# AE350_4GB register map
Vendor: Andes Technology; Series: AE350; File version: 1.3.0
Registers are 32-bit, read-write, reset 0x0 unless marked. A register's access mark holds for its fields unless they carry their own. Offsets are from the block's base; [hi:lo] are bit positions; {n}, {i} and the like mark numbered series; 'fields as' and 'values as' point back to an identical list.

## I_2C — I^2C Controller Registers
Base 0xF0A00000
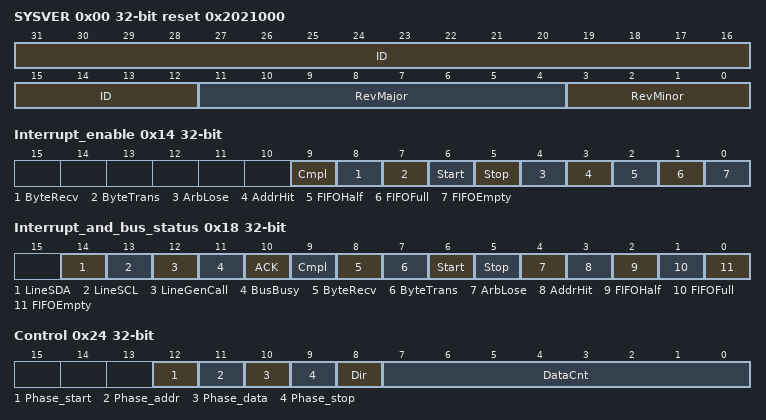
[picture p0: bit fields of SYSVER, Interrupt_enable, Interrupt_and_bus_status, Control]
0x00 SYSVER ro reset 0x2021000 — ID and Revision Register
  [31:12] ID — ID number for ATCIIC100
  [11:4] RevMajor — Major revision number
  [3:0] RevMinor — Minor revision number
0x10 Configuration ro reset not defined
  [1:0] FIFOSize
0x14 Interrupt_enable
  [9] Cmpl — Set to enable the Completion Interrupt
  [8] ByteRecv — Set to enable the Byte Receive Interrupt
  [7] ByteTrans — Set to enable the Byte Transmit Interrupt
  [6] Start — Set to enable the START Condition Interrupt
  [5] Stop — Set to enable the STOP Condition Interrupt
  [4] ArbLose — Set to enable the Arbitration Lose Interrupt
  [3] AddrHit — Set to enable the Address Hit Interrupt
  [2] FIFOHalf — Set to enable the FIFO Half Interrupt
  [1] FIFOFull — Set to enable the FIFO Full Interrupt
  [0] FIFOEmpty — Set to enable the FIFO Empty Interrupt
0x18 Interrupt_and_bus_status
  [14] LineSDA — Indicates the current status of the SDA line on the bus
  [13] LineSCL — Indicates the current status of the SCL line on the bus
  [12] LineGenCall — Indicates that the address of the current transaction is a general call address
  [11] BusBusy — Indicates that the bus is busy
  [10] ACK — Indicates the type of the last received/transmitted acknowledgement bit
  [9] Cmpl — Transaction Completion
  [8] ByteRecv — Indicates that a byte of data has been received
  [7] ByteTrans — Indicates that a byte of data has been transmitted
  [6] Start — Indicates that a START Condition or a repeated START condition has been transmitted/received
  [5] Stop — Indicates that a STOP Condition has been transmitted/received
  [4] ArbLose — Indicates that the controller has lost the bus arbitration
  [3] AddrHit — Master: indicates that a slave has responded to the transaction Slave: indicates that a transaction is targeting the controller (including the General Call)
  [2] FIFOHalf ro — Transmitter: Indicates that the FIFO is half-full. Receiver: Indicates that the FIFO is half-empty.
  [1] FIFOFull ro — Indicates that the FIFO is full
  [0] FIFOEmpty ro — Indicates that the FIFO is empty
0x1C Address
  [9:0] Addr — The slave address
0x20 Data
  [7:0] Data — Write this register to put one byte of data to the FIFO
0x24 Control
  [12] Phase_start — Enable this bit to send a START condition at the beginning of transaction
  [11] Phase_addr — Enable this bit to send the address after START condition
  [10] Phase_data — Enable this bit to send the data after Address phase
  [9] Phase_stop — Enable this bit to send a STOP condition at the end of a transaction
  [8] Dir — Transaction direction
  [7:0] DataCnt — Transaction direction
0x28 Command
  [2:0] CMD — Write this register
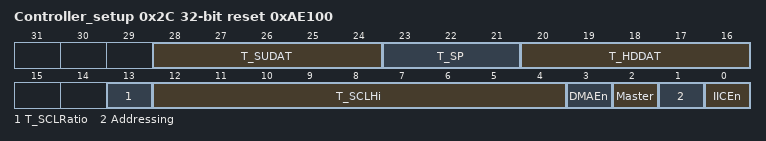
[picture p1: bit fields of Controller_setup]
0x2C Controller_setup reset 0xAE100
  [28:24] T_SUDAT — T_SUDAT defines the data setup time before releasing the SCL
  [23:21] T_SP — T_SP defines the pulse width of spikes that must be suppressed by the input filter
  [20:16] T_HDDAT — T_SUDAT defines the data hold time after SCL goes LOW
  [13] T_SCLRatio — The LOW period of the generated SCL clock is defined by the combination of T_SCLRatio and T_SCLHi values
  [12:4] T_SCLHi — The HIGH period of generated SCL clock is defined by T_SCLHi
  [3] DMAEn — Enable the direct memory access mode data transfer
  [2] Master — Configure this device as a master or a slave
  [1] Addressing — IIC addressing mode
  [0] IICEn — Enable the ATCIIC100 IIC controller
0x30 Timing_Parameter_Multiplier
  [4:0] TPM_TPM

## DMAC — DMA Controller Registers
Base 0xF0C00000
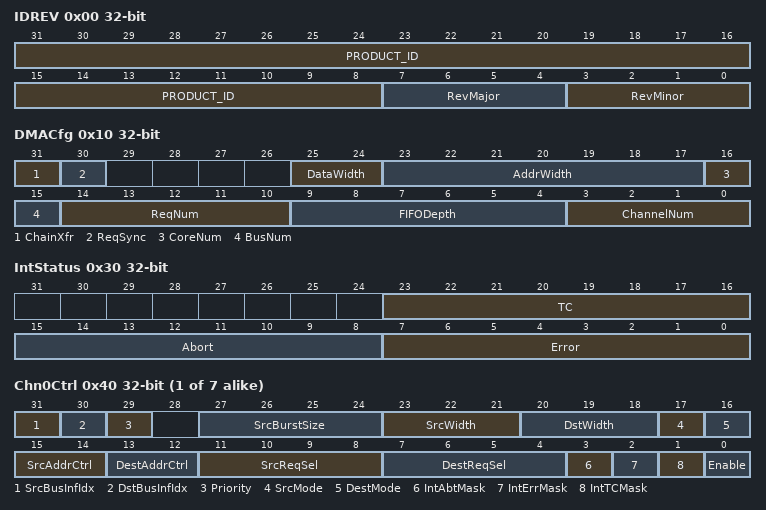
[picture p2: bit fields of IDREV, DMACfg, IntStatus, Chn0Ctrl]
0x00 IDREV ro — ID and Revision Register
  [31:8] PRODUCT_ID — ID number for DMAC(ATCDMAC300 )
  [7:4] RevMajor — Major revision number
  [3:0] RevMinor — Minor revision number
0x10 DMACfg ro — DMAC Configuration Register
  [31] ChainXfr — Chain transfer
  [30] ReqSync — DMA request synchronization
  [25:24] DataWidth — AXI bus data width
  [23:17] AddrWidth — AXI bus address width
  [16] CoreNum — DMA core number
  [15] BusNum — AXI bus interface number
  [14:10] ReqNum — Request/acknowledge pair number
  [9:4] FIFODepth
  [3:0] ChannelNum — Channel number
0x20 DMACtrl — DMAC Control Register
  [0] Reset wo — Software reset control.
0x24 ChAbort wo — Channel Abort Register
  [?] FIELD_1 rw
0x30 IntStatus — Interrupt Status Register
  [23:16] TC — The terminal count status of DMA channels, one bit per channel.
  [15:8] Abort — The abort status of channel, one bit per channel.
  [7:0] Error — The error status, one bit per channel.
0x34 ChEN ro — Channel Enable Register
  [31:0] ChEN — Alias of the Enable field of all ChnCtrl registers
{0x40+0x20*i} Chn{i}Ctrl (i=0..6) — Channel {i} Control Register
  [31] SrcBusInfIdx ro — Bus interface index that source data is read from
  [30] DstBusInfIdx ro — Bus interface index that source data is read from
  [29] Priority ro — Channel priority level
  [27:24] SrcBurstSize ro — Source burst size
  [23:21] SrcWidth ro — Source transfer width
  [20:18] DstWidth ro — Destination transfer width
  [17] SrcMode ro — Source DMA handshake mode
  [16] DestMode ro — Destination DMA handshake mode
  [15:14] SrcAddrCtrl ro — Source address control
  [13:12] DestAddrCtrl ro — Destination address control
  [11:8] SrcReqSel ro — Source DMA request select
  [7:4] DestReqSel ro — Destination DMA request select
  [3] IntAbtMask ro — Channel abort interrupt mask
  [2] IntErrMask ro — Channel error interrupt mask
  [1] IntTCMask ro — Channel terminal count interrupt mask
  [0] Enable ro — Channel enable bit
{0x44+0x20*i} Chn{i}TranSize (i=0..7) — Channel {i} Transfer Size Register
  [?] FIELD_1
{0x48+0x20*i} Chn{i}SrcAddr (i=0..7) — Channel {i} Source Address Register
  [?] FIELD_1
{0x4C+0x20*i} Chn{i}SrcAddrH (i=0..7) — Channel {i} Source Address High Part Register
  [?] FIELD_1
{0x50+0x20*i} Chn{i}DstAddr (i=0..7) — Channel {i} Destination Address Register
  [?] FIELD_1
{0x54+0x20*i} Chn{i}DstAddrH (i=0..7) — Channel {i} Destination Address High Part register
  [?] FIELD_1
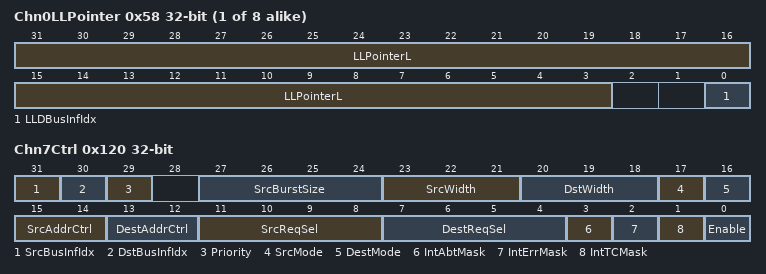
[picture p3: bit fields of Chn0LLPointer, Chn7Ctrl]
{0x58+0x20*i} Chn{i}LLPointer (i=0..7) — Channel {i} Linked List Pointer Register
  [31:3] LLPointerL ro — Low part of the pointer to the next descriptor
  [0] LLDBusInfIdx ro — Bus interface index that the next descriptor is read from
{0x5C+0x20*i} Chn{i}LLPointerH (i=0..7) — Channel {i} Linked List Pointer High Part Register
  [?] FIELD_1
0x120 Chn7Ctrl — Channel 3 Control Register
  fields as Chn0Ctrl
